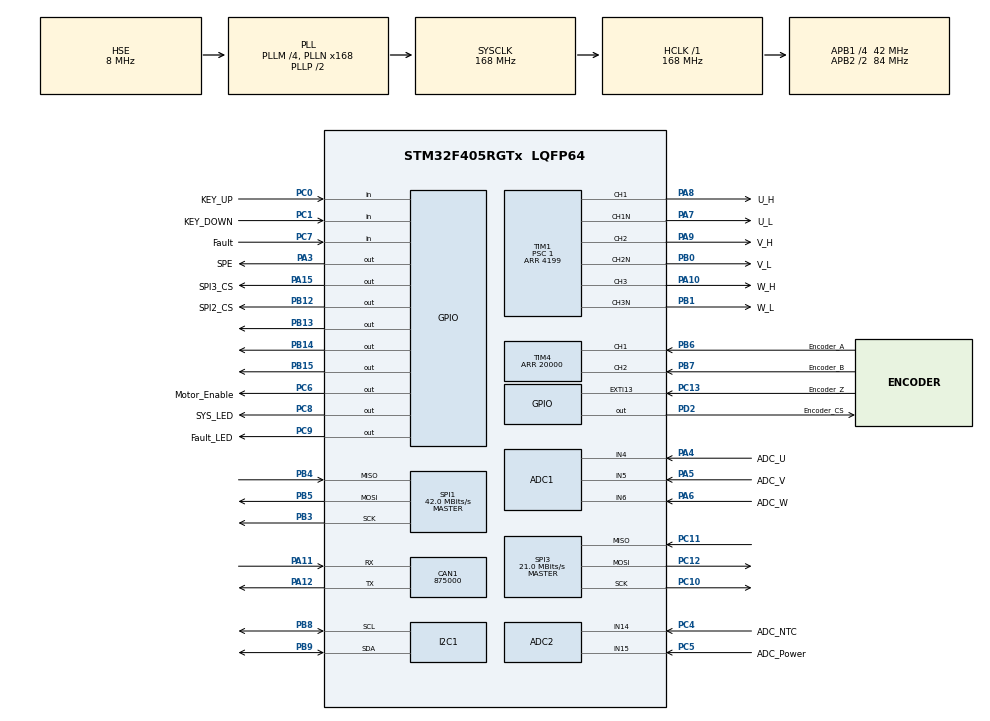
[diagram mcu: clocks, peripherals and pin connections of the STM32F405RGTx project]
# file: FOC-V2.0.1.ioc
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ADC1.Channel-0\#ChannelRegularConversion=ADC_CHANNEL_4
ADC1.Channel-1\#ChannelRegularConversion=ADC_CHANNEL_5
ADC1.Channel-2\#ChannelRegularConversion=ADC_CHANNEL_6
ADC1.ClockPrescaler=ADC_CLOCK_SYNC_PCLK_DIV4
ADC1.DMAContinuousRequests=ENABLE
ADC1.EOCSelection=ADC_EOC_SEQ_CONV
ADC1.NbrOfConversion=3
ADC1.NbrOfConversionFlag=1
ADC1.Rank-0\#ChannelRegularConversion=1
ADC1.Rank-1\#ChannelRegularConversion=2
ADC1.Rank-2\#ChannelRegularConversion=3
ADC1.SamplingTime-0\#ChannelRegularConversion=ADC_SAMPLETIME_3CYCLES
ADC1.SamplingTime-1\#ChannelRegularConversion=ADC_SAMPLETIME_3CYCLES
ADC1.SamplingTime-2\#ChannelRegularConversion=ADC_SAMPLETIME_3CYCLES
ADC1.ScanConvMode=ENABLE
ADC1.master=1
ADC2.Channel-0\#ChannelRegularConversion=ADC_CHANNEL_14
ADC2.ClockPrescaler=ADC_CLOCK_SYNC_PCLK_DIV4
ADC2.NbrOfConversionFlag=1
ADC2.Rank-0\#ChannelRegularConversion=1
ADC2.SamplingTime-0\#ChannelRegularConversion=ADC_SAMPLETIME_3CYCLES
CAN1.BS1=CAN_BS1_1TQ
CAN1.BS2=CAN_BS2_1TQ
CAN1.CalculateBaudRate=875000
CAN1.CalculateTimeBit=1142.85
CAN1.CalculateTimeQuantum=380.95238095238096
Dma.ADC1.0.Direction=DMA_PERIPH_TO_MEMORY
Dma.ADC1.0.FIFOMode=DMA_FIFOMODE_DISABLE
Dma.ADC1.0.Instance=DMA2_Stream0
Dma.ADC1.0.MemDataAlignment=DMA_MDATAALIGN_WORD
Dma.ADC1.0.MemInc=DMA_MINC_ENABLE
Dma.ADC1.0.Mode=DMA_CIRCULAR
Dma.ADC1.0.PeriphDataAlignment=DMA_PDATAALIGN_WORD
Dma.ADC1.0.PeriphInc=DMA_PINC_DISABLE
Dma.ADC1.0.Priority=DMA_PRIORITY_HIGH
Dma.I2C1_TX.1.Direction=DMA_MEMORY_TO_PERIPH
Dma.I2C1_TX.1.FIFOMode=DMA_FIFOMODE_DISABLE
Dma.I2C1_TX.1.Instance=DMA1_Stream7
Dma.I2C1_TX.1.MemDataAlignment=DMA_MDATAALIGN_BYTE
Dma.I2C1_TX.1.MemInc=DMA_MINC_ENABLE
Dma.I2C1_TX.1.Mode=DMA_NORMAL
Dma.I2C1_TX.1.PeriphDataAlignment=DMA_PDATAALIGN_BYTE
Dma.I2C1_TX.1.PeriphInc=DMA_PINC_DISABLE
Dma.I2C1_TX.1.Priority=DMA_PRIORITY_HIGH
Dma.Request0=ADC1
Dma.Request1=I2C1_TX
I2C1.I2C_Mode=I2C_Standard
Mcu.Family=STM32F4
Mcu.Name=STM32F405RGTx
Mcu.Package=LQFP64
NVIC.DMA2_Stream0_IRQn=true\:2\:0\:true\:false\:true\:false\:true
NVIC.EXTI15_10_IRQn=true\:1\:0\:true\:false\:true\:true\:true
NVIC.PriorityGroup=NVIC_PRIORITYGROUP_4
NVIC.TIM1_CC_IRQn=true\:3\:0\:true\:false\:true\:true\:true
PA0-WKUP.Signal=S_TIM2_CH1_ETR
PA1.Signal=S_TIM2_CH2
PA10.GPIO_Label=W_H
PA10.Signal=S_TIM1_CH3
PA11.Mode=CAN_Activate
PA11.Signal=CAN1_RX
PA12.Mode=CAN_Activate
PA12.Signal=CAN1_TX
PA13.Mode=Serial_Wire
PA13.Signal=SYS_JTMS-SWDIO
PA14.Mode=Serial_Wire
PA14.Signal=SYS_JTCK-SWCLK
PA15.GPIO_Label=SPI3_CS
PA15.Signal=GPIO_Output
PA3.GPIO_Label=SPE
PA3.GPIO_PuPd=GPIO_PULLUP
PA3.PinState=GPIO_PIN_RESET
PA3.Signal=GPIO_Output
PA4.GPIO_Label=ADC_U
PA4.Signal=ADCx_IN4
PA5.GPIO_Label=ADC_V
PA5.Signal=ADCx_IN5
PA6.GPIO_Label=ADC_W
PA6.Signal=ADCx_IN6
PA7.GPIO_Label=U_L
PA7.Mode=PWM Generation1 CH1 CH1N
PA7.Signal=TIM1_CH1N
PA8.GPIO_Label=U_H
PA8.Signal=S_TIM1_CH1
PA9.GPIO_Label=V_H
PA9.Signal=S_TIM1_CH2
PB0.GPIO_Label=V_L
PB0.Mode=PWM Generation2 CH2 CH2N
PB0.Signal=TIM1_CH2N
PB1.GPIO_Label=W_L
PB1.Mode=PWM Generation3 CH3 CH3N
PB1.Signal=TIM1_CH3N
PB10.Signal=USART3_TX
PB11.Signal=USART3_RX
PB12.GPIO_Label=SPI2_CS
PB12.Signal=GPIO_Output
PB13.Signal=GPIO_Output
PB14.Signal=GPIO_Output
PB15.Signal=GPIO_Output
PB3.Mode=Full_Duplex_Master
PB3.Signal=SPI1_SCK
PB4.Mode=Full_Duplex_Master
PB4.Signal=SPI1_MISO
PB5.Mode=Full_Duplex_Master
PB5.Signal=SPI1_MOSI
PB6.GPIO_Label=Encoder_A
PB6.Signal=S_TIM4_CH1
PB7.GPIO_Label=Encoder_B
PB7.Signal=S_TIM4_CH2
PB8.Mode=I2C
PB8.Signal=I2C1_SCL
PB9.Mode=I2C
PB9.Signal=I2C1_SDA
PC0.GPIO_Label=KEY_UP
PC0.GPIO_PuPd=GPIO_PULLUP
PC0.Signal=GPIO_Input
PC1.GPIO_Label=KEY_DOWN
PC1.GPIO_PuPd=GPIO_PULLUP
PC1.Signal=GPIO_Input
PC10.Mode=Full_Duplex_Master
PC10.Signal=SPI3_SCK
PC11.Mode=Full_Duplex_Master
PC11.Signal=SPI3_MISO
PC12.Mode=Full_Duplex_Master
PC12.Signal=SPI3_MOSI
PC13-ANTI_TAMP.GPIO_Label=Encoder_Z
PC13-ANTI_TAMP.Signal=GPXTI13
PC4.GPIO_Label=ADC_NTC
PC4.Signal=ADCx_IN14
PC5.GPIO_Label=ADC_Power
PC5.Signal=ADCx_IN15
PC6.GPIO_Label=Motor_Enable
PC6.GPIO_PuPd=GPIO_PULLUP
PC6.GPIO_Speed=GPIO_SPEED_FREQ_MEDIUM
PC6.PinState=GPIO_PIN_RESET
PC6.Signal=GPIO_Output
PC7.GPIO_Label=Fault
PC7.GPIO_Mode=GPIO_MODE_INPUT
PC7.Signal=GPIO_Input
PC8.GPIO_Label=SYS_LED
PC8.GPIO_ModeDefaultOutputPP=GPIO_MODE_OUTPUT_PP
PC8.GPIO_PuPd=GPIO_PULLUP
PC8.GPIO_Speed=GPIO_SPEED_FREQ_LOW
PC8.PinState=GPIO_PIN_RESET
PC8.Signal=GPIO_Output
PC9.GPIO_Label=Fault_LED
PC9.GPIO_ModeDefaultOutputPP=GPIO_MODE_OUTPUT_PP
PC9.GPIO_PuPd=GPIO_PULLUP
PC9.Signal=GPIO_Output
PD2.GPIO_Label=Encoder_CS
PD2.Signal=GPIO_Output
PH0-OSC_IN.Mode=HSE-External-Oscillator
PH0-OSC_IN.Signal=RCC_OSC_IN
PH1-OSC_OUT.Mode=HSE-External-Oscillator
PH1-OSC_OUT.Signal=RCC_OSC_OUT
ProjectManager.HeapSize=0x200
ProjectManager.StackSize=0x400
ProjectManager.TargetToolchain=MDK-ARM V5.27
RCC.48MHZClocksFreq_Value=84000000
RCC.AHBFreq_Value=168000000
RCC.APB1CLKDivider=RCC_HCLK_DIV4
RCC.APB1Freq_Value=42000000
RCC.APB1TimFreq_Value=84000000
RCC.APB2CLKDivider=RCC_HCLK_DIV2
RCC.APB2Freq_Value=84000000
RCC.APB2TimFreq_Value=168000000
RCC.CortexFreq_Value=168000000
RCC.HCLKFreq_Value=168000000
RCC.HSE_VALUE=8000000
RCC.HSI_VALUE=16000000
RCC.LSE_VALUE=32768
RCC.PLLM=4
RCC.PLLN=168
RCC.PLLSourceVirtual=RCC_PLLSOURCE_HSE
RCC.SYSCLKFreq_VALUE=168000000
RCC.SYSCLKSource=RCC_SYSCLKSOURCE_PLLCLK
RCC.VCOOutputFreq_Value=336000000
SH.ADCx_IN14.0=ADC2_IN14,IN14
SH.ADCx_IN15.0=ADC2_IN15,IN15
SH.ADCx_IN4.0=ADC1_IN4,IN4
SH.ADCx_IN5.0=ADC1_IN5,IN5
SH.ADCx_IN6.0=ADC1_IN6,IN6
SH.S_TIM1_CH1.0=TIM1_CH1,PWM Generation1 CH1 CH1N
SH.S_TIM1_CH2.0=TIM1_CH2,PWM Generation2 CH2 CH2N
SH.S_TIM1_CH3.0=TIM1_CH3,PWM Generation3 CH3 CH3N
SH.S_TIM2_CH1_ETR.0=TIM2_CH1
SH.S_TIM2_CH2.0=TIM2_CH2
SH.S_TIM4_CH1.0=TIM4_CH1,Encoder_Interface
SH.S_TIM4_CH2.0=TIM4_CH2,Encoder_Interface
SPI1.BaudRatePrescaler=SPI_BAUDRATEPRESCALER_2
SPI1.CalculateBaudRate=42.0 MBits/s
SPI1.Direction=SPI_DIRECTION_2LINES
SPI1.Mode=SPI_MODE_MASTER
SPI1.VirtualType=VM_MASTER
SPI3.BaudRatePrescaler=SPI_BAUDRATEPRESCALER_2
SPI3.CalculateBaudRate=21.0 MBits/s
SPI3.Direction=SPI_DIRECTION_2LINES
SPI3.Mode=SPI_MODE_MASTER
SPI3.VirtualType=VM_MASTER
TIM1.AutoReloadPreload=TIM_AUTORELOAD_PRELOAD_ENABLE
TIM1.Channel-PWM\ Generation1\ CH1\ CH1N=TIM_CHANNEL_1
TIM1.Channel-PWM\ Generation2\ CH2\ CH2N=TIM_CHANNEL_2
TIM1.Channel-PWM\ Generation3\ CH3\ CH3N=TIM_CHANNEL_3
TIM1.Channel-PWM\ Generation4\ No\ Output=TIM_CHANNEL_4
TIM1.CounterMode=TIM_COUNTERMODE_CENTERALIGNED2
TIM1.DeadTime=100
TIM1.OffStateIDLEMode=TIM_OSSI_ENABLE
TIM1.OffStateRunMode=TIM_OSSR_ENABLE
TIM1.Period=4199
TIM1.Prescaler=1
TIM1.TIM_MasterOutputTrigger=TIM_TRGO_OC4REF
TIM4.EncoderMode=TIM_ENCODERMODE_TI12
TIM4.Period=20000
VP_CRC_VS_CRC.Mode=CRC_Activate
VP_TIM1_VS_ClockSourceINT.Mode=Internal
VP_TIM1_VS_no_output4.Mode=PWM Generation4 No Output
board=custom

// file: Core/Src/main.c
/* USER CODE BEGIN Header */
/**
  ******************************************************************************
  * @file           : main.c
  * @brief          : Main program body
  ******************************************************************************
  * @attention
  *
  * <h2><center>&copy; Copyright (c) 2021 STMicroelectronics.
  * All rights reserved.</center></h2>
  *
  * This software component is licensed by ST under BSD 3-Clause license,
  * the "License"; You may not use this file except in compliance with the
  * License. You may obtain a copy of the License at:
  *                        opensource.org/licenses/BSD-3-Clause
  *
  ******************************************************************************
  */
/* USER CODE END Header */
#include "main.h"
#include "adc.h"
#include "can.h"
#include "crc.h"
#include "dma.h"
#include "i2c.h"
#include "spi.h"
#include "tim.h"
#include "gpio.h"

/* USER CODE BEGIN Includes */
#include "APPMain.h"
/* USER CODE END Includes */

void SystemClock_Config(void);

int main(void)
{

  /* MCU Configuration--------------------------------------------------------*/

  /* Reset of all peripherals, Initializes the Flash interface and the Systick. */
  HAL_Init();

  /* Configure the system clock */
  SystemClock_Config();

  /* Initialize all configured peripherals */
  MX_GPIO_Init();
  MX_DMA_Init();
  MX_ADC1_Init();
  MX_ADC2_Init();
  MX_CAN1_Init();
  MX_I2C1_Init();
  MX_SPI1_Init();
  MX_SPI3_Init();
  MX_TIM1_Init();
  MX_TIM4_Init();
  MX_CRC_Init();
  /* USER CODE BEGIN 2 */
	  APPMain_Init();
  /* USER CODE END 2 */

  /* Infinite loop */
  /* USER CODE BEGIN WHILE */
  while (1)
  {
	  APPMain_Loop();
    /* USER CODE END WHILE */

  }
}

void SystemClock_Config(void)
{
  RCC_OscInitTypeDef RCC_OscInitStruct = {0};
  RCC_ClkInitTypeDef RCC_ClkInitStruct = {0};

  /** Configure the main internal regulator output voltage
  */
  __HAL_RCC_PWR_CLK_ENABLE();
  __HAL_PWR_VOLTAGESCALING_CONFIG(PWR_REGULATOR_VOLTAGE_SCALE1);
  /** Initializes the RCC Oscillators according to the specified parameters
  * in the RCC_OscInitTypeDef structure.
  */
  RCC_OscInitStruct.OscillatorType = RCC_OSCILLATORTYPE_HSE;
  RCC_OscInitStruct.HSEState = RCC_HSE_ON;
  RCC_OscInitStruct.PLL.PLLState = RCC_PLL_ON;
  RCC_OscInitStruct.PLL.PLLSource = RCC_PLLSOURCE_HSE;
  RCC_OscInitStruct.PLL.PLLM = 4;
  RCC_OscInitStruct.PLL.PLLN = 168;
  RCC_OscInitStruct.PLL.PLLP = RCC_PLLP_DIV2;
  RCC_OscInitStruct.PLL.PLLQ = 4;
  if (HAL_RCC_OscConfig(&RCC_OscInitStruct) != HAL_OK)
  {
    Error_Handler();
  }
  /** Initializes the CPU, AHB and APB buses clocks
  */
  RCC_ClkInitStruct.ClockType = RCC_CLOCKTYPE_HCLK|RCC_CLOCKTYPE_SYSCLK
                              |RCC_CLOCKTYPE_PCLK1|RCC_CLOCKTYPE_PCLK2;
  RCC_ClkInitStruct.SYSCLKSource = RCC_SYSCLKSOURCE_PLLCLK;
  RCC_ClkInitStruct.AHBCLKDivider = RCC_SYSCLK_DIV1;
  RCC_ClkInitStruct.APB1CLKDivider = RCC_HCLK_DIV4;
  RCC_ClkInitStruct.APB2CLKDivider = RCC_HCLK_DIV2;

  if (HAL_RCC_ClockConfig(&RCC_ClkInitStruct, FLASH_LATENCY_5) != HAL_OK)
  {
    Error_Handler();
  }
}

void Error_Handler(void)
{
  __disable_irq();
  while (1)
  {
  }
}

/************************ (C) COPYRIGHT STMicroelectronics *****END OF FILE****/
